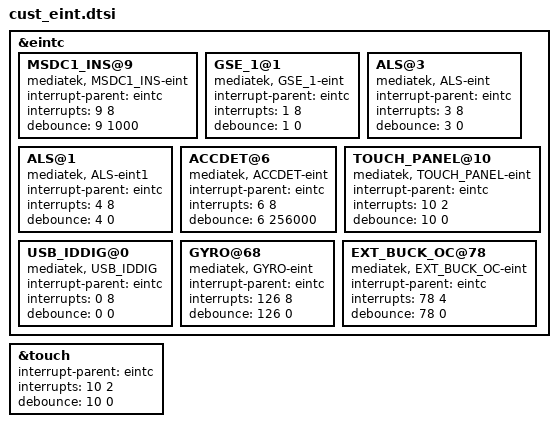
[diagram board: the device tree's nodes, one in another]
/*
 * Generated by MTK SP Drv_CodeGen Version 03.13.6  for MT6735. Copyright MediaTek Inc. (C) 2013.
 * Thu May 28 10:14:14 2015
 * Do Not Modify the File.
 */

/*************************
 * EINT DTSI File
*************************/

#include <dt-bindings/interrupt-controller/irq.h>
#include <dt-bindings/interrupt-controller/arm-gic.h>
/*
&nfc {
	interrupt-parent = <&eintc>;
	interrupts = <2 IRQ_TYPE_LEVEL_HIGH>;
	debounce = <2 0>;
	status = "okay";
};
*/
&eintc {
/*
	IRQ_NFC@2 {
		compatible = "mediatek, IRQ_NFC-eint";
		interrupt-parent = <&eintc>;
		interrupts = <2 4>;
		debounce = <2 0>;
	};
 
*/

	MSDC1_INS@9 {
		compatible = "mediatek, MSDC1_INS-eint";
		interrupt-parent = <&eintc>;
		interrupts = <9 8>;
		debounce = <9 1000>;
	};
	/*   qma6981  interrupt setting */
	GSE_1@1 {
		compatible = "mediatek, GSE_1-eint";
		interrupt-parent = <&eintc>;
		interrupts = <1 8>;
		debounce = <1 0>;
	};
	
	ALS@3 {
		compatible = "mediatek, ALS-eint";
		interrupt-parent = <&eintc>;
		interrupts = <3 8>;
		debounce = <3 0>;
	};
	ALS@1 {
		compatible = "mediatek, ALS-eint1";
		interrupt-parent = <&eintc>;
		interrupts = <4 8>;
		debounce = <4 0>;
	};
	/*
	FP@5 {
		compatible = "mediatek, FP-eint";
		interrupt-parent = <&eintc>;
		interrupts = <5 8>;
		debounce = <5 1000>;
	};
	*/
	ACCDET@6 {
		compatible = "mediatek, ACCDET-eint";
		interrupt-parent = <&eintc>;
		interrupts = <6 8>;
		debounce = <6 256000>;
	};

	TOUCH_PANEL@10 {
		compatible = "mediatek, TOUCH_PANEL-eint";
		interrupt-parent = <&eintc>;
		interrupts = <10 2>;
		debounce = <10 0>;
	};

 USB_IDDIG@0{
    compatible = "mediatek, USB_IDDIG";
		interrupt-parent = <&eintc>;
		interrupts = <0 8>;
		debounce = <0 0>;
   
   };

	GYRO@68 {
		compatible = "mediatek, GYRO-eint";
		interrupt-parent = <&eintc>;
		interrupts = <126 8>;
		debounce = <126 0>;
	};

	EXT_BUCK_OC@78 {
		compatible = "mediatek, EXT_BUCK_OC-eint";
		interrupt-parent = <&eintc>;
		interrupts = <78 4>;
		debounce = <78 0>;
	};
 
};
&touch {
	interrupt-parent = <&eintc>;
	interrupts = <10 2>;
	debounce = <10 0>;
};
